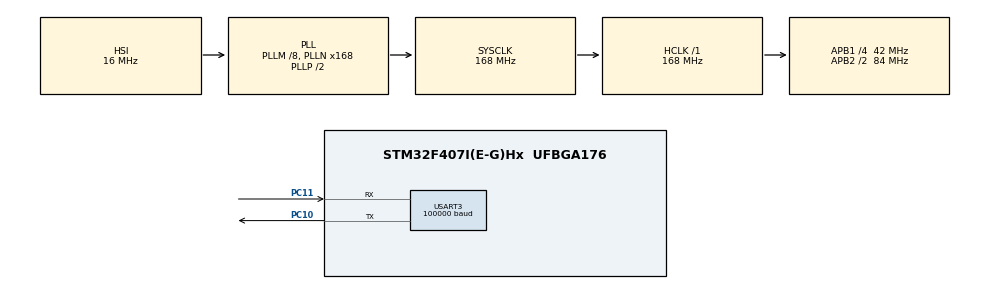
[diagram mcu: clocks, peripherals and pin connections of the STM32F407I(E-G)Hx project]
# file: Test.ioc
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Dma.Request0=USART3_RX
Dma.USART3_RX.0.Direction=DMA_PERIPH_TO_MEMORY
Dma.USART3_RX.0.FIFOMode=DMA_FIFOMODE_DISABLE
Dma.USART3_RX.0.Instance=DMA1_Stream1
Dma.USART3_RX.0.MemDataAlignment=DMA_MDATAALIGN_BYTE
Dma.USART3_RX.0.MemInc=DMA_MINC_ENABLE
Dma.USART3_RX.0.Mode=DMA_NORMAL
Dma.USART3_RX.0.PeriphDataAlignment=DMA_PDATAALIGN_BYTE
Dma.USART3_RX.0.PeriphInc=DMA_PINC_DISABLE
Dma.USART3_RX.0.Priority=DMA_PRIORITY_LOW
Mcu.Family=STM32F4
Mcu.Name=STM32F407I(E-G)Hx
Mcu.Package=UFBGA176
NVIC.DMA1_Stream1_IRQn=true\:0\:0\:false\:false\:true\:false\:true\:true
NVIC.PriorityGroup=NVIC_PRIORITYGROUP_4
NVIC.USART3_IRQn=true\:0\:0\:false\:false\:true\:true\:true\:true
PA13.Mode=Serial_Wire
PA13.Signal=SYS_JTMS-SWDIO
PA14.Mode=Serial_Wire
PA14.Signal=SYS_JTCK-SWCLK
PC10.Mode=Asynchronous
PC10.Signal=USART3_TX
PC11.Mode=Asynchronous
PC11.Signal=USART3_RX
PH0-OSC_IN.Mode=HSE-External-Oscillator
PH0-OSC_IN.Signal=RCC_OSC_IN
PH1-OSC_OUT.Mode=HSE-External-Oscillator
PH1-OSC_OUT.Signal=RCC_OSC_OUT
ProjectManager.HeapSize=0x200
ProjectManager.StackSize=0x400
ProjectManager.TargetToolchain=Makefile
RCC.48MHZClocksFreq_Value=84000000
RCC.AHBFreq_Value=168000000
RCC.APB1CLKDivider=RCC_HCLK_DIV4
RCC.APB1Freq_Value=42000000
RCC.APB1TimFreq_Value=84000000
RCC.APB2CLKDivider=RCC_HCLK_DIV2
RCC.APB2Freq_Value=84000000
RCC.APB2TimFreq_Value=168000000
RCC.CortexFreq_Value=168000000
RCC.HCLKFreq_Value=168000000
RCC.HSE_VALUE=12000000
RCC.HSI_VALUE=16000000
RCC.LSE_VALUE=32768
RCC.PLLM=8
RCC.PLLN=168
RCC.SYSCLKFreq_VALUE=168000000
RCC.SYSCLKSource=RCC_SYSCLKSOURCE_PLLCLK
RCC.VCOOutputFreq_Value=336000000
USART3.BaudRate=100000
USART3.Parity=PARITY_EVEN
USART3.StopBits=STOPBITS_2
USART3.VirtualMode=VM_ASYNC
USART3.WordLength=WORDLENGTH_9B
board=custom

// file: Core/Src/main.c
/* USER CODE BEGIN Header */
/**
  ******************************************************************************
  * @file           : main.c
  * @brief          : Main program body
  ******************************************************************************
  * @attention
  *
  * Copyright (c) 2026 STMicroelectronics.
  * All rights reserved.
  *
  * This software is licensed under terms that can be found in the LICENSE file
  * in the root directory of this software component.
  * If no LICENSE file comes with this software, it is provided AS-IS.
  *
  ******************************************************************************
  */
/* USER CODE END Header */
#include "main.h"
#include "dma.h"
#include "usart.h"
#include "gpio.h"

/* USER CODE BEGIN PTD */
typedef struct{
  int16_t rocker_l;     //左水平
  int16_t rocker_l1;    //左竖直
  int16_t rocker_r;     //右水平
  int16_t rocker_r1;    //右竖直

  int16_t sw1;          //开关1
  int16_t sw2;          //2
  int16_t sw3;          //3
  int16_t sw4;          //4

  int16_t vr1;          //旋钮1
  int16_t vr2;          //2

  int16_t b_lose;       //帧丢失标志位
  int16_t er_protect;   //故障保护激活位
}rc_data;
/* USER CODE END PTD */

/* USER CODE BEGIN PD */
static rc_data ch_data; //通道值。static让变量只能在当前文件调用。
uint8_t raw_data[256];  //原始数据
int16_t ch[16];         //解析值减去1024
uint8_t start_byte;
uint8_t flat_byte;      //标志位
uint8_t stop_byte;      //停止位
volatile uint8_t state=0;
volatile uint8_t error_time=0;

void HAL_UARTEx_RxEventCallback(UART_HandleTypeDef *huart, uint16_t Size){
  if(huart==&huart3){
    state=1;
  }
}

void HAL_UART_ErrorCallback(UART_HandleTypeDef *huart){
  if(huart==&huart3){
    error_time+=1;
    HAL_UARTEx_ReceiveToIdle_DMA(&huart3,raw_data,25);
    __HAL_DMA_DISABLE_IT(huart3.hdmarx,DMA_IT_HT);
  }
}
/* USER CODE END PD */

void SystemClock_Config(void);

int main(void)
{

  /* MCU Configuration--------------------------------------------------------*/

  /* Reset of all peripherals, Initializes the Flash interface and the Systick. */
  HAL_Init();

  /* Configure the system clock */
  SystemClock_Config();

  /* Initialize all configured peripherals */
  MX_GPIO_Init();
  MX_DMA_Init();
  MX_USART3_UART_Init();
  /* USER CODE BEGIN 2 */
  HAL_UARTEx_ReceiveToIdle_DMA(&huart3,raw_data,25);
    __HAL_DMA_DISABLE_IT(huart3.hdmarx,DMA_IT_HT);
  /* USER CODE END 2 */

  /* Infinite loop */
  /* USER CODE BEGIN WHILE */
  while (1)
  {
    if(state==1){
      state=0;

      start_byte=raw_data[0];

      ch[0]=( ( (int16_t)raw_data[0]>>0 | (int16_t)raw_data[1]<<8 ) & 0x07FF ) -1024;
      ch[1]=( ( (int16_t)raw_data[1]>>3 | (int16_t)raw_data[2]<<5 ) & 0x07FF ) -1024;
      ch[2]=( ( (int16_t)raw_data[2]>>6 | (int16_t)raw_data[3]<<2 | (int16_t)raw_data[4]<<10 ) & 0x07FF ) -1024;
      ch[3]=( ( (int16_t)raw_data[4]>>1 | (int16_t)raw_data[5]<<7 ) & 0x07FF ) -1024;
      ch[4]=( ( (int16_t)raw_data[5]>>4 | (int16_t)raw_data[6]<<4 ) & 0x07FF ) -1024;
      ch[5]=( ( (int16_t)raw_data[6]>>7 | (int16_t)raw_data[7]<<1 | (int16_t)raw_data[8]<<9 ) & 0x07FF ) -1024;
      ch[6]=( ( (int16_t)raw_data[8]>>2 | (int16_t)raw_data[9]<<6 ) & 0x07FF ) -1024;
      ch[7]=( ( (int16_t)raw_data[9]>>5 | (int16_t)raw_data[10]<<3 ) & 0x07FF ) -1024;
      ch[8]=( ( (int16_t)raw_data[10]>>8 | (int16_t)raw_data[11]<<0 | (int16_t)raw_data[12]<<8 ) & 0x07FF ) -1024;
      ch[9]=( ( (int16_t)raw_data[12]>>3 | (int16_t)raw_data[13]<<5 ) & 0x07FF ) -1024;
      flat_byte=raw_data[23];
      stop_byte=raw_data[24];

    ch_data.rocker_l=ch[3];
    ch_data.rocker_l1=ch[2];
    ch_data.rocker_r=ch[1];
    ch_data.rocker_r1=ch[0];

    ch_data.sw1=ch[6];
    ch_data.sw2=ch[7];
    ch_data.sw3=ch[8];
    ch_data.sw4=ch[9];

    ch_data.vr1=ch[4];
    ch_data.vr2=ch[5];

      ch_data.b_lose=(flat_byte>>2)&0x01;
      ch_data.er_protect=(flat_byte>>3)&0x01;

      HAL_UARTEx_ReceiveToIdle_DMA(&huart3,raw_data,25);
      __HAL_DMA_DISABLE_IT(huart3.hdmarx,DMA_IT_HT);
  }
    /* USER CODE END WHILE */

  }
}

void SystemClock_Config(void)
{
  RCC_OscInitTypeDef RCC_OscInitStruct = {0};
  RCC_ClkInitTypeDef RCC_ClkInitStruct = {0};

  /** Configure the main internal regulator output voltage
  */
  __HAL_RCC_PWR_CLK_ENABLE();
  __HAL_PWR_VOLTAGESCALING_CONFIG(PWR_REGULATOR_VOLTAGE_SCALE1);

  /** Initializes the RCC Oscillators according to the specified parameters
  * in the RCC_OscInitTypeDef structure.
  */
  RCC_OscInitStruct.OscillatorType = RCC_OSCILLATORTYPE_HSI;
  RCC_OscInitStruct.HSIState = RCC_HSI_ON;
  RCC_OscInitStruct.HSICalibrationValue = RCC_HSICALIBRATION_DEFAULT;
  RCC_OscInitStruct.PLL.PLLState = RCC_PLL_ON;
  RCC_OscInitStruct.PLL.PLLSource = RCC_PLLSOURCE_HSI;
  RCC_OscInitStruct.PLL.PLLM = 8;
  RCC_OscInitStruct.PLL.PLLN = 168;
  RCC_OscInitStruct.PLL.PLLP = RCC_PLLP_DIV2;
  RCC_OscInitStruct.PLL.PLLQ = 4;
  if (HAL_RCC_OscConfig(&RCC_OscInitStruct) != HAL_OK)
  {
    Error_Handler();
  }

  /** Initializes the CPU, AHB and APB buses clocks
  */
  RCC_ClkInitStruct.ClockType = RCC_CLOCKTYPE_HCLK|RCC_CLOCKTYPE_SYSCLK
                              |RCC_CLOCKTYPE_PCLK1|RCC_CLOCKTYPE_PCLK2;
  RCC_ClkInitStruct.SYSCLKSource = RCC_SYSCLKSOURCE_PLLCLK;
  RCC_ClkInitStruct.AHBCLKDivider = RCC_SYSCLK_DIV1;
  RCC_ClkInitStruct.APB1CLKDivider = RCC_HCLK_DIV4;
  RCC_ClkInitStruct.APB2CLKDivider = RCC_HCLK_DIV2;

  if (HAL_RCC_ClockConfig(&RCC_ClkInitStruct, FLASH_LATENCY_5) != HAL_OK)
  {
    Error_Handler();
  }
}

void Error_Handler(void)
{
  __disable_irq();
  while (1)
  {
  }
}
